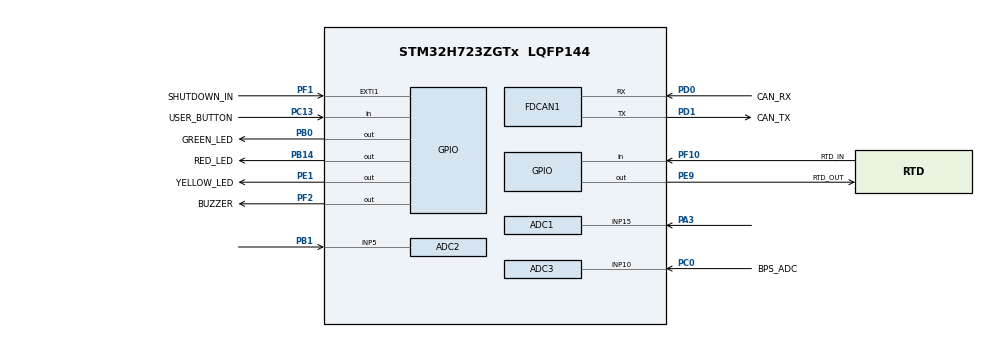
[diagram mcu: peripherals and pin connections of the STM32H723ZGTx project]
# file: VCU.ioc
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ADC1.Channel-9\#ChannelRegularConversion=ADC_CHANNEL_15
ADC1.NbrOfConversionFlag=1
ADC1.OffsetNumber-9\#ChannelRegularConversion=ADC_OFFSET_NONE
ADC1.OffsetSignedSaturation-9\#ChannelRegularConversion=DISABLE
ADC1.Rank-9\#ChannelRegularConversion=1
ADC1.SamplingTime-9\#ChannelRegularConversion=ADC_SAMPLETIME_1CYCLE_5
ADC1.master=1
ADC2.Channel-10\#ChannelRegularConversion=ADC_CHANNEL_5
ADC2.NbrOfConversionFlag=1
ADC2.OffsetNumber-10\#ChannelRegularConversion=ADC_OFFSET_NONE
ADC2.OffsetSignedSaturation-10\#ChannelRegularConversion=DISABLE
ADC2.Rank-10\#ChannelRegularConversion=1
ADC2.SamplingTime-10\#ChannelRegularConversion=ADC_SAMPLETIME_1CYCLE_5
ADC3.Channel-0\#ChannelRegularConversion=ADC_CHANNEL_10
ADC3.NbrOfConversionFlag=1
ADC3.OffsetNumber-0\#ChannelRegularConversion=ADC_OFFSET_NONE
ADC3.OffsetSaturation-0\#ChannelRegularConversion=DISABLE
ADC3.OffsetSign-0\#ChannelRegularConversion=ADC3_OFFSET_SIGN_NEGATIVE
ADC3.Rank-0\#ChannelRegularConversion=1
ADC3.SamplingTime-0\#ChannelRegularConversion=ADC3_SAMPLETIME_2CYCLES_5
FDCAN1.DataTimeSeg1=31
FDCAN1.DataTimeSeg2=16
FDCAN1.Mode=FDCAN_MODE_NORMAL
FDCAN1.NominalSyncJumpWidth=8
FDCAN1.NominalTimeSeg1=31
FDCAN1.NominalTimeSeg2=8
FDCAN1.RxBuffersNbr=4
FDCAN1.RxFifo0ElmtsNbr=2
FDCAN1.StdFiltersNbr=1
FDCAN1.TxBuffersNbr=2
FDCAN1.TxEventsNbr=2
FDCAN1.TxFifoQueueElmtsNbr=2
Mcu.Family=STM32H7
Mcu.Name=STM32H723ZGTx
Mcu.Package=LQFP144
NVIC.EXTI1_IRQn=true\:0\:0\:false\:false\:true\:false\:true\:true\:true
NVIC.FDCAN1_IT0_IRQn=true\:0\:0\:false\:false\:true\:false\:true\:true\:true
NVIC.PriorityGroup=NVIC_PRIORITYGROUP_4
NVIC.TIM3_IRQn=true\:15\:0\:false\:false\:true\:false\:false\:true\:true
NVIC.TimeBase=TIM3_IRQn
NVIC.TimeBaseIP=TIM3
PA3.Signal=ADCx_INP15
PB0.GPIO_Label=GREEN_LED
PB0.Signal=GPIO_Output
PB1.Signal=ADCx_INP5
PB14.GPIO_Label=RED_LED
PB14.Signal=GPIO_Output
PC0.GPIO_Label=BPS_ADC
PC0.Signal=ADCx_INP10
PC13.GPIO_Label=USER_BUTTON
PC13.Signal=GPIO_Input
PD0.GPIO_Label=CAN_RX
PD0.Mode=FDCAN_Activate
PD0.Signal=FDCAN1_RX
PD1.GPIO_Label=CAN_TX
PD1.Mode=FDCAN_Activate
PD1.Signal=FDCAN1_TX
PE1.GPIO_Label=YELLOW_LED
PE1.Signal=GPIO_Output
PE9.GPIO_Label=RTD_OUT
PE9.GPIO_PuPd=GPIO_NOPULL
PE9.GPIO_Speed=GPIO_SPEED_FREQ_VERY_HIGH
PE9.PinState=GPIO_PIN_SET
PE9.Signal=GPIO_Output
PF1.GPIO_Label=SHUTDOWN_IN
PF1.GPIO_PuPd=GPIO_NOPULL
PF1.Signal=GPXTI1
PF10.GPIO_Label=RTD_IN
PF10.Signal=GPIO_Input
PF2.GPIO_Label=BUZZER
PF2.Signal=GPIO_Output
ProjectManager.HeapSize=0x200
ProjectManager.StackSize=0x400
ProjectManager.TargetToolchain=Makefile
RCC.ADCFreq_Value=38400000
RCC.APB1Freq_Value=32000000
RCC.APB2Freq_Value=32000000
RCC.APB3Freq_Value=32000000
RCC.APB4Freq_Value=32000000
RCC.CortexFreq_Value=64000000
RCC.D1PPRE=RCC_APB3_DIV2
RCC.D2PPRE1=RCC_APB1_DIV2
RCC.D2PPRE2=RCC_APB2_DIV2
RCC.D3PPRE=RCC_APB4_DIV2
RCC.DIVM1=4
RCC.DIVM2=4
RCC.DIVN1=12
RCC.DIVN2=12
RCC.DIVP2=5
RCC.DIVQ1=5
RCC.HCLKFreq_Value=64000000
RCC.PLL2FRACN=0
RCC.PLLFRACN=4096
RCC.SYSCLKFreq_VALUE=64000000
RCC.USBFreq_Value=40000000
SH.ADCx_INP10.0=ADC3_INP10,IN10-Single-Ended
SH.ADCx_INP15.0=ADC1_INP15,IN15-Single-Ended
SH.ADCx_INP5.0=ADC2_INP5,IN5-Single-Ended
STMicroelectronics.X-CUBE-AZRTOS-H7.2.0.0.TX_APP_MEM_POOL_SIZE=10000
STMicroelectronics.X-CUBE-AZRTOS-H7.2.0.0.TX_ENABLE_EVENT_TRACE=1
STMicroelectronics.X-CUBE-AZRTOS-H7.2.0.0.TX_TIMER_TICKS_PER_SECOND=1000
STMicroelectronics.X-CUBE-AZRTOS-H7.2.0.0.ThreadXCcRTOSJjThreadXJjCore=true
STMicroelectronics.X-CUBE-AZRTOS-H7.2.0.0.ThreadXCcRTOSJjThreadXJjTraceXOosupport=true
STMicroelectronics.X-CUBE-AZRTOS-H7.2.0.0_IsAnAzureRtosMw=true
VP_RTC_VS_RTC_Activate.Mode=RTC_Enabled
VP_STMicroelectronics.X-CUBE-AZRTOS-H7_VS_RTOSJjThreadX_6.1.7_2.0.0.Mode=RTOSJjThreadX
VP_SYS_VS_tim3.Mode=TIM3
board=custom

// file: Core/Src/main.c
/* USER CODE BEGIN Header */
/**
  ******************************************************************************
  * @file           : main.c
  * @brief          : Main program body
  ******************************************************************************
  * @attention
  *
  * <h2><center>&copy; Copyright (c) 2021 STMicroelectronics.
  * All rights reserved.</center></h2>
  *
  * This software component is licensed by ST under BSD 3-Clause license,
  * the "License"; You may not use this file except in compliance with the
  * License. You may obtain a copy of the License at:
  *                        opensource.org/licenses/BSD-3-Clause
  *
  ******************************************************************************
  */
/* USER CODE END Header */
#include "main.h"
#include "app_threadx.h"
#include "adc.h"
#include "fdcan.h"
#include "rtc.h"
#include "gpio.h"

/* USER CODE BEGIN Includes */
#include "fault.h"
/* USER CODE END Includes */

void SystemClock_Config(void);
void PeriphCommonClock_Config(void);

int main(void)
{

  /* MCU Configuration--------------------------------------------------------*/

  /* Reset of all peripherals, Initializes the Flash interface and the Systick. */
  HAL_Init();

  /* Configure the system clock */
  SystemClock_Config();

/* Configure the peripherals common clocks */
  PeriphCommonClock_Config();

  /* Initialize all configured peripherals */
  MX_GPIO_Init();
  MX_ADC1_Init();
  MX_FDCAN1_Init();
  MX_ADC2_Init();
  MX_RTC_Init();
  MX_ADC3_Init();

  MX_ThreadX_Init();

  /* We should never get here as control is now taken by the scheduler */
  /* Infinite loop */
  while (1)
  {

  }
}

void SystemClock_Config(void)
{
  RCC_OscInitTypeDef RCC_OscInitStruct = {0};
  RCC_ClkInitTypeDef RCC_ClkInitStruct = {0};

  /** Supply configuration update enable
  */
  HAL_PWREx_ConfigSupply(PWR_LDO_SUPPLY);

  /** Configure the main internal regulator output voltage
  */
  __HAL_PWR_VOLTAGESCALING_CONFIG(PWR_REGULATOR_VOLTAGE_SCALE3);

  while(!__HAL_PWR_GET_FLAG(PWR_FLAG_VOSRDY)) {}

  /** Macro to configure the PLL clock source
  */
  __HAL_RCC_PLL_PLLSOURCE_CONFIG(RCC_PLLSOURCE_HSI);

  /** Initializes the RCC Oscillators according to the specified parameters
  * in the RCC_OscInitTypeDef structure.
  */
  RCC_OscInitStruct.OscillatorType = RCC_OSCILLATORTYPE_HSI|RCC_OSCILLATORTYPE_LSI;
  RCC_OscInitStruct.HSIState = RCC_HSI_DIV1;
  RCC_OscInitStruct.HSICalibrationValue = RCC_HSICALIBRATION_DEFAULT;
  RCC_OscInitStruct.LSIState = RCC_LSI_ON;
  RCC_OscInitStruct.PLL.PLLState = RCC_PLL_ON;
  RCC_OscInitStruct.PLL.PLLSource = RCC_PLLSOURCE_HSI;
  RCC_OscInitStruct.PLL.PLLM = 4;
  RCC_OscInitStruct.PLL.PLLN = 12;
  RCC_OscInitStruct.PLL.PLLP = 2;
  RCC_OscInitStruct.PLL.PLLQ = 5;
  RCC_OscInitStruct.PLL.PLLR = 2;
  RCC_OscInitStruct.PLL.PLLRGE = RCC_PLL1VCIRANGE_3;
  RCC_OscInitStruct.PLL.PLLVCOSEL = RCC_PLL1VCOWIDE;
  RCC_OscInitStruct.PLL.PLLFRACN = 4096;
  if (HAL_RCC_OscConfig(&RCC_OscInitStruct) != HAL_OK)
  {
    Error_Handler();
  }

  /** Initializes the CPU, AHB and APB buses clocks
  */
  RCC_ClkInitStruct.ClockType = RCC_CLOCKTYPE_HCLK|RCC_CLOCKTYPE_SYSCLK
                              |RCC_CLOCKTYPE_PCLK1|RCC_CLOCKTYPE_PCLK2
                              |RCC_CLOCKTYPE_D3PCLK1|RCC_CLOCKTYPE_D1PCLK1;
  RCC_ClkInitStruct.SYSCLKSource = RCC_SYSCLKSOURCE_HSI;
  RCC_ClkInitStruct.SYSCLKDivider = RCC_SYSCLK_DIV1;
  RCC_ClkInitStruct.AHBCLKDivider = RCC_HCLK_DIV1;
  RCC_ClkInitStruct.APB3CLKDivider = RCC_APB3_DIV2;
  RCC_ClkInitStruct.APB1CLKDivider = RCC_APB1_DIV2;
  RCC_ClkInitStruct.APB2CLKDivider = RCC_APB2_DIV2;
  RCC_ClkInitStruct.APB4CLKDivider = RCC_APB4_DIV2;

  if (HAL_RCC_ClockConfig(&RCC_ClkInitStruct, FLASH_LATENCY_1) != HAL_OK)
  {
    Error_Handler();
  }
}

void PeriphCommonClock_Config(void)
{
  RCC_PeriphCLKInitTypeDef PeriphClkInitStruct = {0};

  /** Initializes the peripherals clock
  */
  PeriphClkInitStruct.PeriphClockSelection = RCC_PERIPHCLK_ADC;
  PeriphClkInitStruct.PLL2.PLL2M = 4;
  PeriphClkInitStruct.PLL2.PLL2N = 12;
  PeriphClkInitStruct.PLL2.PLL2P = 5;
  PeriphClkInitStruct.PLL2.PLL2Q = 2;
  PeriphClkInitStruct.PLL2.PLL2R = 2;
  PeriphClkInitStruct.PLL2.PLL2RGE = RCC_PLL2VCIRANGE_3;
  PeriphClkInitStruct.PLL2.PLL2VCOSEL = RCC_PLL2VCOWIDE;
  PeriphClkInitStruct.PLL2.PLL2FRACN = 0;
  PeriphClkInitStruct.AdcClockSelection = RCC_ADCCLKSOURCE_PLL2;
  if (HAL_RCCEx_PeriphCLKConfig(&PeriphClkInitStruct) != HAL_OK)
  {
    Error_Handler();
  }
}

void HAL_TIM_PeriodElapsedCallback(TIM_HandleTypeDef *htim)
{
  if (htim->Instance == TIM3) {
    HAL_IncTick();
  }
}

void Error_Handler(void)
{
  /* USER CODE BEGIN Error_Handler_Debug */
  /* User can add his own implementation to report the HAL error return state */
  __disable_irq();
  while (1)
  {
    HAL_GPIO_WritePin(RED_LED_GPIO_Port, RED_LED_Pin, GPIO_PIN_SET);
    HAL_GPIO_WritePin(YELLOW_LED_GPIO_Port, YELLOW_LED_Pin, GPIO_PIN_SET);
  }
  /* USER CODE END Error_Handler_Debug */
}
